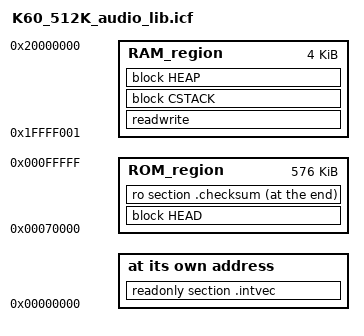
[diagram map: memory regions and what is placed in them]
/*###ICF### Section handled by ICF editor, don't touch! ****/
/*-Editor annotation file-*/
/* IcfEditorFile="$TOOLKIT_DIR$\config\ide\IcfEditor\cortex_v1_0.xml" */
/*-Specials-*/
define symbol __ICFEDIT_intvec_start__ = 0x00000000;
/*-Memory Regions-*/
define symbol __ICFEDIT_region_ROM_start__ = 0x00070000;
define symbol __ICFEDIT_region_ROM_end__   = 0x000FFFFF;
define symbol __ICFEDIT_region_RAM_start__ = 0x1FFFF001;
define symbol __ICFEDIT_region_RAM_end__   = 0x20000000;
/*-Sizes-*/
define symbol __ICFEDIT_size_cstack__ = 0x0;
define symbol __ICFEDIT_size_heap__   = 0x0;
/**** End of ICF editor section. ###ICF###*/

define memory mem with size = 4G;
define region ROM_region = mem:[from __ICFEDIT_region_ROM_start__ to __ICFEDIT_region_ROM_end__];
define region RAM_region   = mem:[from __ICFEDIT_region_RAM_start__  to __ICFEDIT_region_RAM_end__];

define block CSTACK    with alignment = 8, size = __ICFEDIT_size_cstack__   { };
define block HEAP      with alignment = 8, size = __ICFEDIT_size_heap__     { };

initialize by copy { readwrite };
do not initialize  { section .noinit };

define block HEAD with alignment = 4, fixed order
{
ro object lib.o,
ro,
ro data
};

"INTVEC":
place at address mem:__ICFEDIT_intvec_start__ { readonly section .intvec };

"ROM":
place in ROM_region   { block HEAD };

"RAM":
place in RAM_region   { readwrite, block CSTACK, block HEAP };

"CHECKSUM":
place at end of ROM_region { ro section .checksum };
keep { section .checksum };
 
